# AT90CAN128 register map
Vendor: Atmel; File version: 1.0
CPU: other r0p0, little endian, no MPU, no FPU, 4 interrupt priority bits
Registers are 8-bit, read-write, reset 0x0 unless marked. A register's access mark holds for its fields unless they carry their own. Offsets are from the block's base; [hi:lo] are bit positions.

## TC1 — Timer/Counter, 16-bit
Base 0x00000036
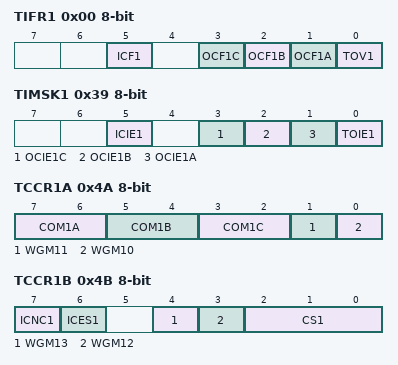
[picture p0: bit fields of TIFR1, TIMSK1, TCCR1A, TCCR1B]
0x00 TIFR1 — Timer/Counter Interrupt Flag register
  [5] ICF1 — Input Capture Flag 1
  [3] OCF1C — Output Compare Flag 1C
  [2] OCF1B — Output Compare Flag 1B
  [1] OCF1A — Output Compare Flag 1A
  [0] TOV1 — Timer/Counter1 Overflow Flag
0x39 TIMSK1 — Timer/Counter Interrupt Mask Register
  [5] ICIE1 — Timer/Counter1 Input Capture Interrupt Enable
  [3] OCIE1C — Timer/Counter1 Output CompareC Match Interrupt Enable
  [2] OCIE1B — Timer/Counter1 Output CompareB Match Interrupt Enable
  [1] OCIE1A — Timer/Counter1 Output CompareA Match Interrupt Enable
  [0] TOIE1 — Timer/Counter1 Overflow Interrupt Enable
0x4A TCCR1A — Timer/Counter1 Control Register A
  [7:6] COM1A — Compare Output Mode 1A, bits
  [5:4] COM1B — Compare Output Mode 1B, bits
  [3:2] COM1C — Compare Output Mode 1C, bits
  [1] WGM11 — Waveform Generation Mode
  [0] WGM10 — Waveform Generation Mode
0x4B TCCR1B — Timer/Counter1 Control Register B
  [7] ICNC1 — Input Capture 1 Noise Canceler
  [6] ICES1 — Input Capture 1 Edge Select
  [4] WGM13 — Waveform Generation Mode
  [3] WGM12 — Waveform Generation Mode
  [2:0] CS1 — Prescaler source of Timer/Counter 1
    0=No Clock Source (Stopped); 1=Running, No Prescaling; 2=Running, CLK/8; 3=Running, CLK/64; 4=Running, CLK/256; 5=Running, CLK/1024; 6=Running, ExtClk Tx Falling Edge; 7=Running, ExtClk Tx Rising Edge
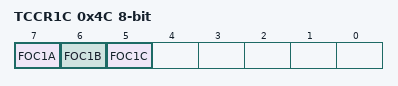
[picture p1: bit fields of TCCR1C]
0x4C TCCR1C — Timer/Counter 1 Control Register C
  [7] FOC1A — Force Output Compare 1A
  [6] FOC1B — Force Output Compare 1B
  [5] FOC1C — Force Output Compare 1C
0x4E TCNT1 16-bit (reset mask 0xFF) — Timer/Counter1 Bytes
0x50 ICR1 16-bit (reset mask 0xFF) — Timer/Counter1 Input Capture Register Bytes
0x52 OCR1A 16-bit (reset mask 0xFF) — Timer/Counter1 Output Compare Register Bytes
0x54 OCR1B 16-bit (reset mask 0xFF) — Timer/Counter1 Output Compare Register Bytes
0x56 OCR1C 16-bit (reset mask 0xFF) — Timer/Counter1 Output Compare Register Bytes

## TC2 — Timer/Counter, 8-bit Async
Base 0x00000037
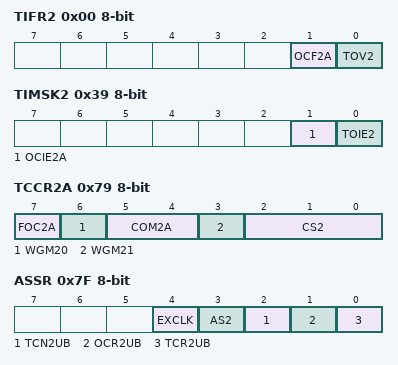
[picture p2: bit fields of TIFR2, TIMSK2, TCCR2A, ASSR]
0x00 TIFR2 — Timer/Counter Interrupt Flag Register
  [1] OCF2A — Output Compare Flag 2
  [0] TOV2 — Timer/Counter2 Overflow Flag
0x0C GTCCR — General Timer/Counter Control Register
  [1] PSR2 — Prescaler Reset Timer/Counter2
0x39 TIMSK2 — Timer/Counter Interrupt Mask register
  [1] OCIE2A — Timer/Counter2 Output Compare Match Interrupt Enable
  [0] TOIE2 — Timer/Counter2 Overflow Interrupt Enable
0x79 TCCR2A — Timer/Counter2 Control Register
  [7] FOC2A — Force Output Compare
  [6] WGM20 — Waveform Genration Mode
    0=Normal; 1=CTC
  [5:4] COM2A — Compare Output Mode bits
  [3] WGM21 — Waveform Generation Mode
  [2:0] CS2 — Clock Select bits
    0=No Clock Source (Stopped); 1=Running, No Prescaling; 2=Running, CLK/8; 3=Running, CLK/32; 4=Running, CLK/64; 5=Running, CLK/128; 6=Running, CLK/256; 7=Running, CLK/1024
0x7B TCNT2 — Timer/Counter2
0x7C OCR2A — Timer/Counter2 Output Compare Register
0x7F ASSR — Asynchronous Status Register
  [4] EXCLK — Enable External Clock Interrupt
  [3] AS2 — AS2: Asynchronous Timer/Counter2
  [2] TCN2UB — TCN2UB: Timer/Counter2 Update Busy
  [1] OCR2UB — Output Compare Register2 Update Busy
  [0] TCR2UB — TCR2UB: Timer/Counter Control Register2 Update Busy

## TC3 — Timer/Counter, 16-bit
Base 0x00000038
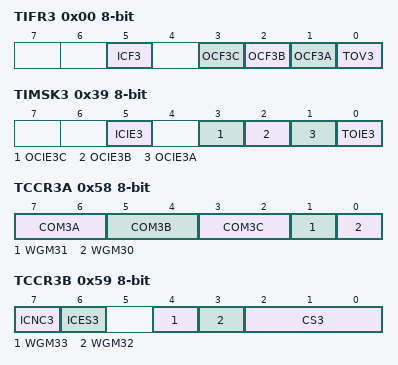
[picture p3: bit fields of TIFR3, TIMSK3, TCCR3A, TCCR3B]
0x00 TIFR3 — Timer/Counter Interrupt Flag register
  [5] ICF3 — Input Capture Flag 3
  [3] OCF3C — Output Compare Flag 3C
  [2] OCF3B — Output Compare Flag 3B
  [1] OCF3A — Output Compare Flag 3A
  [0] TOV3 — Timer/Counter3 Overflow Flag
0x39 TIMSK3 — Timer/Counter Interrupt Mask Register
  [5] ICIE3 — Timer/Counter3 Input Capture Interrupt Enable
  [3] OCIE3C — Timer/Counter3 Output CompareC Match Interrupt Enable
  [2] OCIE3B — Timer/Counter3 Output CompareB Match Interrupt Enable
  [1] OCIE3A — Timer/Counter3 Output CompareA Match Interrupt Enable
  [0] TOIE3 — Timer/Counter3 Overflow Interrupt Enable
0x58 TCCR3A — Timer/Counter3 Control Register A
  [7:6] COM3A — Compare Output Mode 3A, bits
  [5:4] COM3B — Compare Output Mode 3B, bits
  [3:2] COM3C — Compare Output Mode 3C, bits
  [1] WGM31 — Waveform Generation Mode
  [0] WGM30 — Waveform Generation Mode
0x59 TCCR3B — Timer/Counter3 Control Register B
  [7] ICNC3 — Input Capture 3 Noise Canceler
  [6] ICES3 — Input Capture 3 Edge Select
  [4] WGM33 — Waveform Generation Mode
  [3] WGM32 — Waveform Generation Mode
  [2:0] CS3 — Prescaler source of Timer/Counter 3
    0=No Clock Source (Stopped); 1=Running, No Prescaling; 2=Running, CLK/8; 3=Running, CLK/64; 4=Running, CLK/256; 5=Running, CLK/1024; 6=Running, ExtClk Tx Falling Edge; 7=Running, ExtClk Tx Rising Edge
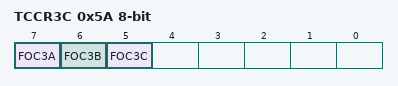
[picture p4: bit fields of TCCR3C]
0x5A TCCR3C — Timer/Counter 3 Control Register C
  [7] FOC3A — Force Output Compare 3A
  [6] FOC3B — Force Output Compare 3B
  [5] FOC3C — Force Output Compare 3C
0x5C TCNT3 16-bit (reset mask 0xFF) — Timer/Counter3 Bytes
0x5E ICR3 16-bit (reset mask 0xFF) — Timer/Counter3 Input Capture Register Bytes
0x60 OCR3A 16-bit (reset mask 0xFF) — Timer/Counter3 Output Compare Register Bytes
0x62 OCR3B 16-bit (reset mask 0xFF) — Timer/Counter3 Output Compare Register Bytes
0x64 OCR3C 16-bit (reset mask 0xFF) — Timer/Counter3 Output Compare Register Bytes

## TWI — Two Wire Serial Interface
Base 0x000000B8
0x00 TWBR — TWI Bit Rate register
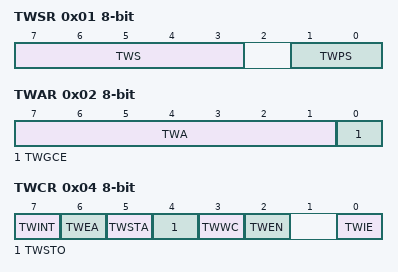
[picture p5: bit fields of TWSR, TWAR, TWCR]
0x01 TWSR — TWI Status Register
  [7:3] TWS — TWI Status
  [1:0] TWPS — TWI Prescaler
    0=1; 1=4; 2=16; 3=64
0x02 TWAR — TWI (Slave) Address register
  [7:1] TWA — TWI (Slave) Address register Bits
  [0] TWGCE — TWI General Call Recognition Enable Bit
0x03 TWDR — TWI Data register
0x04 TWCR — TWI Control Register
  [7] TWINT — TWI Interrupt Flag
  [6] TWEA — TWI Enable Acknowledge Bit
  [5] TWSTA — TWI Start Condition Bit
  [4] TWSTO — TWI Stop Condition Bit
  [3] TWWC — TWI Write Collition Flag
  [2] TWEN — TWI Enable Bit
  [0] TWIE — TWI Interrupt Enable

## USART0 — USART
Base 0x000000C0
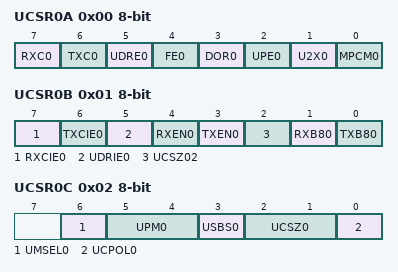
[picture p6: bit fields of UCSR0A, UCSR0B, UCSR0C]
0x00 UCSR0A — USART Control and Status Register A
  [7] RXC0 — USART Receive Complete
  [6] TXC0 — USART Transmitt Complete
  [5] UDRE0 — USART Data Register Empty
  [4] FE0 — Framing Error
  [3] DOR0 — Data overRun
  [2] UPE0 — Parity Error
  [1] U2X0 — Double the USART transmission speed
  [0] MPCM0 — Multi-processor Communication Mode
0x01 UCSR0B — USART Control and Status Register B
  [7] RXCIE0 — RX Complete Interrupt Enable
  [6] TXCIE0 — TX Complete Interrupt Enable
  [5] UDRIE0 — USART Data register Empty Interrupt Enable
  [4] RXEN0 — Receiver Enable
  [3] TXEN0 — Transmitter Enable
  [2] UCSZ02 — Character Size
  [1] RXB80 — Receive Data Bit 8
  [0] TXB80 — Transmit Data Bit 8
0x02 UCSR0C — USART Control and Status Register C
  [6] UMSEL0 — USART Mode Select
    0=Asynchronous Operation; 1=Synchronous Operation
  [5:4] UPM0 — Parity Mode Bits
    0=Disabled; 2=Enabled, Even Parity; 3=Enabled, Odd Parity
  [3] USBS0 — Stop Bit Select
    0=1-bit; 1=2-bit
  [2:1] UCSZ0 — Character Size
  [0] UCPOL0 — Clock Polarity
0x04 UBRR0 16-bit (reset mask 0xFF) — USART Baud Rate Register t Bytes
0x06 UDR0 — USART I/O Data Register

## USART1 — USART
Base 0x000000C8
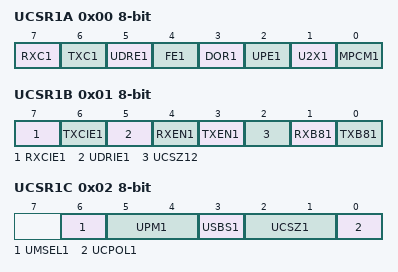
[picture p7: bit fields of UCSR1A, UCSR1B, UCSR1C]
0x00 UCSR1A — USART Control and Status Register A
  [7] RXC1 — USART Receive Complete
  [6] TXC1 — USART Transmitt Complete
  [5] UDRE1 — USART Data Register Empty
  [4] FE1 — Framing Error
  [3] DOR1 — Data overRun
  [2] UPE1 — Parity Error
  [1] U2X1 — Double the USART transmission speed
  [0] MPCM1 — Multi-processor Communication Mode
0x01 UCSR1B — USART Control and Status Register B
  [7] RXCIE1 — RX Complete Interrupt Enable
  [6] TXCIE1 — TX Complete Interrupt Enable
  [5] UDRIE1 — USART Data register Empty Interrupt Enable
  [4] RXEN1 — Receiver Enable
  [3] TXEN1 — Transmitter Enable
  [2] UCSZ12 — Character Size
  [1] RXB81 — Receive Data Bit 8
  [0] TXB81 — Transmit Data Bit 8
0x02 UCSR1C — USART Control and Status Register C
  [6] UMSEL1 — USART Mode Select
    0=Asynchronous Operation; 1=Synchronous Operation
  [5:4] UPM1 — Parity Mode Bits
    0=Disabled; 2=Enabled, Even Parity; 3=Enabled, Odd Parity
  [3] USBS1 — Stop Bit Select
    0=1-bit; 1=2-bit
  [2:1] UCSZ1 — Character Size
  [0] UCPOL1 — Clock Polarity
0x04 UBRR1 16-bit (reset mask 0xFF) — USART Baud Rate Register t Bytes
0x06 UDR1 — USART I/O Data Register

## WDT — Watchdog Timer
Base 0x00000060
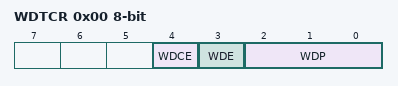
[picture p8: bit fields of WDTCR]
0x00 WDTCR — Watchdog Timer Control Register
  [4] WDCE — Watchdog Change Enable
  [3] WDE — Watch Dog Enable
  [2:0] WDP — Watch Dog Timer Prescaler bits
    0=Oscillator Cycles 16K; 1=Oscillator Cycles 32K; 2=Oscillator Cycles 64K; 3=Oscillator Cycles 128K; 4=Oscillator Cycles 256K; 5=Oscillator Cycles 512K; 6=Oscillator Cycles 1024K; 7=Oscillator Cycles 2048K
